# STM32H7A3x register map
File version: 2.0
CPU: CM7 r0p1, little endian, MPU, FPU, 4 interrupt priority bits
Registers are 32-bit, read-write, reset 0x0 unless marked. A register's access mark holds for its fields unless they carry their own. Offsets are from the block's base; [hi:lo] are bit positions; {n}, {i} and the like mark numbered series.

## DELAY_Block_SDMMC1
Base 0x52008000
Same registers: DELAY_Block_SDMMC2 0x48022800, Delay_Block_OCTOSPI1 0x52006000, Delay_Block_OCTOSPI2 0x5200B000
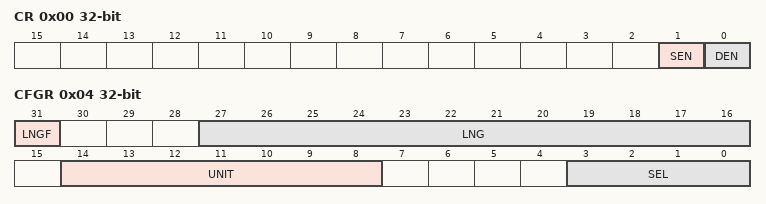
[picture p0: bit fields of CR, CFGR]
0x00 CR — DLYB control register
  [1] SEN — Sampler length enable bit
  [0] DEN — Delay block enable bit
0x04 CFGR — DLYB configuration register
  [31] LNGF — Length valid flag
  [27:16] LNG — Delay line length value
  [14:8] UNIT — Delay Defines the delay of a Unit delay cell
  [3:0] SEL — Select the phase for the Output clock

## DMAMUX1 — DMAMUX
Base 0x40020800
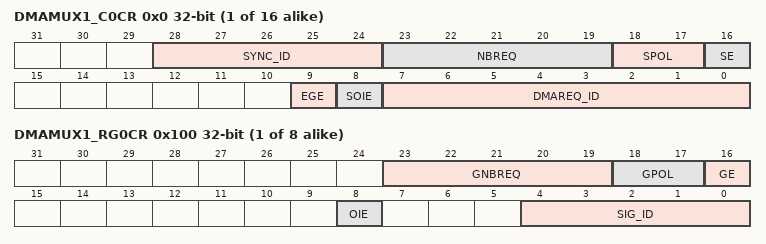
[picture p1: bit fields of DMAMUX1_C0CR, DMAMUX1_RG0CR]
{0x0+4i} DMAMUX1_C{i}CR (i=0..15) — DMAMux - DMA request line multiplexer channel x control register
  [28:24] SYNC_ID — Synchronization input selected
  [23:19] NBREQ — Number of DMA requests to forward Defines the number of DMA requests forwarded before output event is generated. In synchronous mode, it also defines the number of DMA requests to forward after a synchronization event, then stop forwarding. The actual number of DMA requests forwarded is NBREQ+1. Note: This field can only be written when both SE and EGE bits are reset.
  [18:17] SPOL — Synchronization event type selector Defines the synchronization event on the selected synchronization input:
  [16] SE — Synchronous operating mode enable/disable
  [9] EGE — Event generation enable/disable
  [8] SOIE — Interrupt enable at synchronization event overrun
  [7:0] DMAREQ_ID — Input DMA request line selected
0x80 DMAMUX1_CSR ro — DMAMUX request line multiplexer interrupt channel status register
  [15:0] SOF — Synchronization overrun event flag
0x84 DMAMUX1_CFR wo — DMAMUX request line multiplexer interrupt clear flag register
  [15:0] CSOF — Clear synchronization overrun event flag
{0x100+4i} DMAMUX1_RG{i}CR (i=0..7) — DMAMux - DMA request generator channel x control register
  [23:19] GNBREQ — Number of DMA requests to generate Defines the number of DMA requests generated after a trigger event, then stop generating. The actual number of generated DMA requests is GNBREQ+1. Note: This field can only be written when GE bit is reset.
  [18:17] GPOL — DMA request generator trigger event type selection Defines the trigger event on the selected DMA request trigger input
  [16] GE — DMA request generator channel enable/disable
  [8] OIE — Interrupt enable at trigger event overrun
  [4:0] SIG_ID — DMA request trigger input selected
0x140 DMAMUX1_RGSR ro — DMAMux - DMA request generator status register
  [7:0] OF — Trigger event overrun flag The flag is set when a trigger event occurs on DMA request generator channel x, while the DMA request generator counter value is lower than GNBREQ. The flag is cleared by writing 1 to the corresponding COFx bit in DMAMUX_RGCFR register.
0x144 DMAMUX1_RGCFR wo — DMAMux - DMA request generator clear flag register
  [7:0] COF — Clear trigger event overrun flag Upon setting, this bit clears the corresponding overrun flag OFx in the DMAMUX_RGCSR register.

## DMAMUX2 — DMAMUX
Base 0x58025800
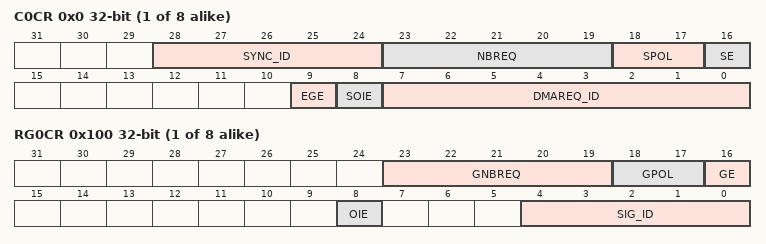
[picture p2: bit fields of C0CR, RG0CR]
{0x0+4i} C{i}CR (i=0..7) — DMAMux - DMA request line multiplexer channel x control register
  [28:24] SYNC_ID — Synchronization input selected
  [23:19] NBREQ — Number of DMA requests to forward Defines the number of DMA requests forwarded before output event is generated. In synchronous mode, it also defines the number of DMA requests to forward after a synchronization event, then stop forwarding. The actual number of DMA requests forwarded is NBREQ+1. Note: This field can only be written when both SE and EGE bits are reset.
  [18:17] SPOL — Synchronization event type selector Defines the synchronization event on the selected synchronization input:
  [16] SE — Synchronous operating mode enable/disable
  [9] EGE — Event generation enable/disable
  [8] SOIE — Interrupt enable at synchronization event overrun
  [7:0] DMAREQ_ID — Input DMA request line selected
0x80 CSR ro — DMAMUX request line multiplexer interrupt channel status register
  [15:0] SOF — Synchronization overrun event flag
0x84 CFR wo — DMAMUX request line multiplexer interrupt clear flag register
  [15:0] CSOF — Clear synchronization overrun event flag
{0x100+4i} RG{i}CR (i=0..7) — DMAMux - DMA request generator channel x control register
  [23:19] GNBREQ — Number of DMA requests to generate Defines the number of DMA requests generated after a trigger event, then stop generating. The actual number of generated DMA requests is GNBREQ+1. Note: This field can only be written when GE bit is reset.
  [18:17] GPOL — DMA request generator trigger event type selection Defines the trigger event on the selected DMA request trigger input
  [16] GE — DMA request generator channel enable/disable
  [8] OIE — Interrupt enable at trigger event overrun
  [4:0] SIG_ID — DMA request trigger input selected
0x140 RGSR ro — DMAMux - DMA request generator status register
  [7:0] OF — Trigger event overrun flag The flag is set when a trigger event occurs on DMA request generator channel x, while the DMA request generator counter value is lower than GNBREQ. The flag is cleared by writing 1 to the corresponding COFx bit in DMAMUX_RGCFR register.
0x144 RGCFR wo — DMAMux - DMA request generator clear flag register
  [7:0] COF — Clear trigger event overrun flag Upon setting, this bit clears the corresponding overrun flag OFx in the DMAMUX_RGCSR register.
